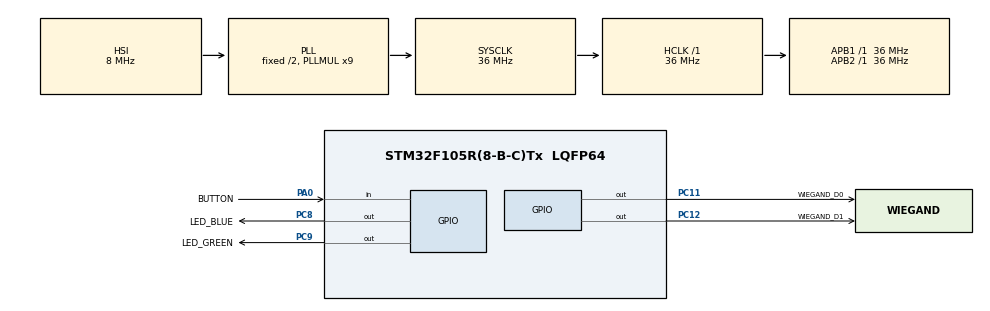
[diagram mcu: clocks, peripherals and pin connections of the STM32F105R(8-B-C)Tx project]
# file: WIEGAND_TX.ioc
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Mcu.Family=STM32F1
PC9.GPIO_Label=LED_GREEN
PC12.Signal=GPIO_Output
PC11.Signal=GPIO_Output
PC8.Signal=GPIO_Output
TIM6.Prescaler=35
VP_TIM6_VS_ClockSourceINT.Mode=Enable_Timer
RCC.SYSCLKSource=RCC_SYSCLKSOURCE_PLLCLK
ProjectManager.StackSize=0x400
PA0-WKUP.GPIO_Label=BUTTON
PA0-WKUP.Signal=GPIO_Input
NVIC.TIM6_IRQn=true\:0\:0\:false\:false\:true\:true\:true
PC8.GPIO_Label=LED_BLUE
VP_TIM7_VS_ClockSourceINT.Mode=Enable_Timer
PA13.Signal=SYS_JTMS-SWDIO
ProjectManager.TargetToolchain=STM32CubeIDE
RCC.HCLKFreq_Value=36000000
RCC.APB2TimFreq_Value=36000000
TIM7.Period=999
RCC.USBFreq_Value=24000000
RCC.AHBFreq_Value=36000000
TIM7.Prescaler=35
board=custom
RCC.PLLMUL=RCC_PLL_MUL9
RCC.APB2Freq_Value=36000000
PA14.Mode=Serial_Wire
PC11.GPIO_Label=WIEGAND_D0
PA13.Mode=Serial_Wire
Mcu.Name=STM32F105R(8-B-C)Tx
RCC.SYSCLKFreq_VALUE=36000000
Mcu.Package=LQFP64
PC12.GPIO_Label=WIEGAND_D1
PA14.Signal=SYS_JTCK-SWCLK
ProjectManager.HeapSize=0x200
NVIC.PriorityGroup=NVIC_PRIORITYGROUP_4
RCC.APB1TimFreq_Value=36000000
PC9.Signal=GPIO_Output
RCC.APB1Freq_Value=36000000
NVIC.TIM7_IRQn=true\:0\:0\:false\:false\:true\:true\:true

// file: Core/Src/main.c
/* USER CODE BEGIN Header */
/**
  ******************************************************************************
  * @file           : main.c
  * @brief          : Main program body
  ******************************************************************************
  * @attention
  *
  * <h2><center>&copy; Copyright (c) 2021 STMicroelectronics.
  * All rights reserved.</center></h2>
  *
  * This software component is licensed by ST under BSD 3-Clause license,
  * the "License"; You may not use this file except in compliance with the
  * License. You may obtain a copy of the License at:
  *                        opensource.org/licenses/BSD-3-Clause
  *
  ******************************************************************************
  */
/* USER CODE END Header */
#include "main.h"

/* USER CODE BEGIN Includes */
#include "wiegand.h"
/* USER CODE END Includes */

TIM_HandleTypeDef htim6;
TIM_HandleTypeDef htim7;

void SystemClock_Config(void);
static void MX_GPIO_Init(void);
static void MX_TIM6_Init(void);
static void MX_TIM7_Init(void);

int main(void)
{

  /* MCU Configuration--------------------------------------------------------*/

  /* Reset of all peripherals, Initializes the Flash interface and the Systick. */
  HAL_Init();

  /* Configure the system clock */
  SystemClock_Config();

  /* Initialize all configured peripherals */
  MX_GPIO_Init();
  MX_TIM6_Init();
  MX_TIM7_Init();
  /* USER CODE BEGIN 2 */
  WiegandInit(&htim6);
  HAL_TIM_Base_Start_IT(&htim7);
  /* USER CODE END 2 */

  /* Infinite loop */
  while (1)
  {

  }
}

void SystemClock_Config(void)
{
  RCC_OscInitTypeDef RCC_OscInitStruct = {0};
  RCC_ClkInitTypeDef RCC_ClkInitStruct = {0};

  /** Initializes the RCC Oscillators according to the specified parameters
  * in the RCC_OscInitTypeDef structure.
  */
  RCC_OscInitStruct.OscillatorType = RCC_OSCILLATORTYPE_HSI;
  RCC_OscInitStruct.HSIState = RCC_HSI_ON;
  RCC_OscInitStruct.HSICalibrationValue = RCC_HSICALIBRATION_DEFAULT;
  RCC_OscInitStruct.Prediv1Source = RCC_PREDIV1_SOURCE_HSE;
  RCC_OscInitStruct.PLL.PLLState = RCC_PLL_ON;
  RCC_OscInitStruct.PLL.PLLSource = RCC_PLLSOURCE_HSI_DIV2;
  RCC_OscInitStruct.PLL.PLLMUL = RCC_PLL_MUL9;
  RCC_OscInitStruct.PLL2.PLL2State = RCC_PLL_NONE;
  if (HAL_RCC_OscConfig(&RCC_OscInitStruct) != HAL_OK)
  {
    Error_Handler();
  }
  /** Initializes the CPU, AHB and APB buses clocks
  */
  RCC_ClkInitStruct.ClockType = RCC_CLOCKTYPE_HCLK|RCC_CLOCKTYPE_SYSCLK
                              |RCC_CLOCKTYPE_PCLK1|RCC_CLOCKTYPE_PCLK2;
  RCC_ClkInitStruct.SYSCLKSource = RCC_SYSCLKSOURCE_PLLCLK;
  RCC_ClkInitStruct.AHBCLKDivider = RCC_SYSCLK_DIV1;
  RCC_ClkInitStruct.APB1CLKDivider = RCC_HCLK_DIV1;
  RCC_ClkInitStruct.APB2CLKDivider = RCC_HCLK_DIV1;

  if (HAL_RCC_ClockConfig(&RCC_ClkInitStruct, FLASH_LATENCY_1) != HAL_OK)
  {
    Error_Handler();
  }
  /** Configure the Systick interrupt time
  */
  __HAL_RCC_PLLI2S_ENABLE();
}

static void MX_TIM6_Init(void)
{

  TIM_MasterConfigTypeDef sMasterConfig = {0};

  htim6.Instance = TIM6;
  htim6.Init.Prescaler = 35;
  htim6.Init.CounterMode = TIM_COUNTERMODE_UP;
  htim6.Init.Period = 65535;
  htim6.Init.AutoReloadPreload = TIM_AUTORELOAD_PRELOAD_DISABLE;
  if (HAL_TIM_Base_Init(&htim6) != HAL_OK)
  {
    Error_Handler();
  }
  sMasterConfig.MasterOutputTrigger = TIM_TRGO_RESET;
  sMasterConfig.MasterSlaveMode = TIM_MASTERSLAVEMODE_DISABLE;
  if (HAL_TIMEx_MasterConfigSynchronization(&htim6, &sMasterConfig) != HAL_OK)
  {
    Error_Handler();
  }

}

static void MX_TIM7_Init(void)
{

  TIM_MasterConfigTypeDef sMasterConfig = {0};

  htim7.Instance = TIM7;
  htim7.Init.Prescaler = 35;
  htim7.Init.CounterMode = TIM_COUNTERMODE_UP;
  htim7.Init.Period = 999;
  htim7.Init.AutoReloadPreload = TIM_AUTORELOAD_PRELOAD_DISABLE;
  if (HAL_TIM_Base_Init(&htim7) != HAL_OK)
  {
    Error_Handler();
  }
  sMasterConfig.MasterOutputTrigger = TIM_TRGO_RESET;
  sMasterConfig.MasterSlaveMode = TIM_MASTERSLAVEMODE_DISABLE;
  if (HAL_TIMEx_MasterConfigSynchronization(&htim7, &sMasterConfig) != HAL_OK)
  {
    Error_Handler();
  }

}

static void MX_GPIO_Init(void)
{
  GPIO_InitTypeDef GPIO_InitStruct = {0};

  /* GPIO Ports Clock Enable */
  __HAL_RCC_GPIOA_CLK_ENABLE();
  __HAL_RCC_GPIOC_CLK_ENABLE();

  /*Configure GPIO pin Output Level */
  HAL_GPIO_WritePin(GPIOC, LED_BLUE_Pin|LED_GREEN_Pin|WIEGAND_D0_Pin|WIEGAND_D1_Pin, GPIO_PIN_RESET);

  /*Configure GPIO pin : BUTTON_Pin */
  GPIO_InitStruct.Pin = BUTTON_Pin;
  GPIO_InitStruct.Mode = GPIO_MODE_INPUT;
  GPIO_InitStruct.Pull = GPIO_NOPULL;
  HAL_GPIO_Init(BUTTON_GPIO_Port, &GPIO_InitStruct);

  /*Configure GPIO pins : LED_BLUE_Pin LED_GREEN_Pin WIEGAND_D0_Pin WIEGAND_D1_Pin */
  GPIO_InitStruct.Pin = LED_BLUE_Pin|LED_GREEN_Pin|WIEGAND_D0_Pin|WIEGAND_D1_Pin;
  GPIO_InitStruct.Mode = GPIO_MODE_OUTPUT_PP;
  GPIO_InitStruct.Pull = GPIO_NOPULL;
  GPIO_InitStruct.Speed = GPIO_SPEED_FREQ_LOW;
  HAL_GPIO_Init(GPIOC, &GPIO_InitStruct);

}

void Error_Handler(void)
{
  __disable_irq();
  while (1)
  {
  }
}

/************************ (C) COPYRIGHT STMicroelectronics *****END OF FILE****/
